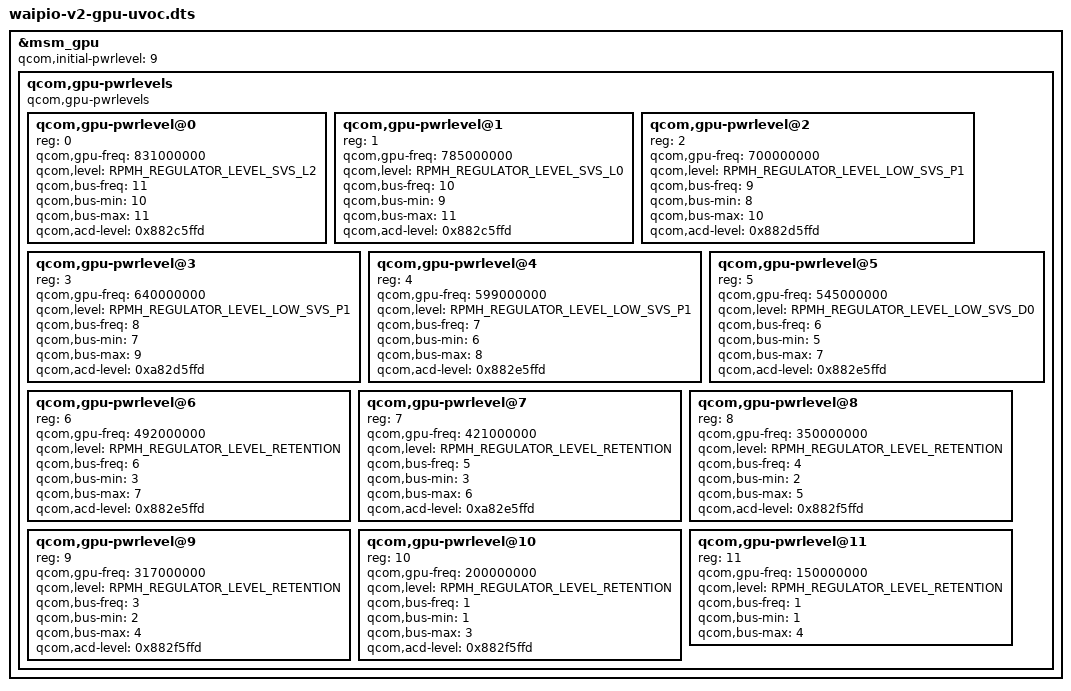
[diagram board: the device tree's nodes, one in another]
/*
 * DoraCore: waipio-v2.dtb with an Adreno 730 undervolt + overclock
 * power level table, from the KonaBess profile "new 831-150 uv_oc".
 * Generated by tools/gen-gpu-profiles.py; only the GPU (GX) rail
 * levels change, CX votes stay as stock. Running the GPU outside the
 * stock table may crash, freeze or damage the device.
 */

#include "waipio-v2.dts"

&msm_gpu {
	/delete-node/ qcom,gpu-pwrlevels;
};

&msm_gpu {
	qcom,initial-pwrlevel = <9>;

	qcom,gpu-pwrlevels {
		#address-cells = <1>;
		#size-cells = <0>;

		compatible = "qcom,gpu-pwrlevels";

		/* 831 MHz (not in stock, profile level 193) */
		qcom,gpu-pwrlevel@0 {
			reg = <0>;
			qcom,gpu-freq = <831000000>;
			qcom,level = <RPMH_REGULATOR_LEVEL_SVS_L2>;

			qcom,bus-freq = <11>;
			qcom,bus-min = <10>;
			qcom,bus-max = <11>;

			qcom,acd-level = <0x882c5ffd>;
		};

		/* 785 MHz (not in stock, profile level 129) */
		qcom,gpu-pwrlevel@1 {
			reg = <1>;
			qcom,gpu-freq = <785000000>;
			qcom,level = <RPMH_REGULATOR_LEVEL_SVS_L0>;

			qcom,bus-freq = <10>;
			qcom,bus-min = <9>;
			qcom,bus-max = <11>;

			qcom,acd-level = <0x882c5ffd>;
		};

		/* 700 MHz (not in stock, profile level 65) */
		qcom,gpu-pwrlevel@2 {
			reg = <2>;
			qcom,gpu-freq = <700000000>;
			qcom,level = <RPMH_REGULATOR_LEVEL_LOW_SVS_P1>;

			qcom,bus-freq = <9>;
			qcom,bus-min = <8>;
			qcom,bus-max = <10>;

			qcom,acd-level = <0x882d5ffd>;
		};

		/* 640 MHz (stock SVS_L2, profile level 65) */
		qcom,gpu-pwrlevel@3 {
			reg = <3>;
			qcom,gpu-freq = <640000000>;
			qcom,level = <RPMH_REGULATOR_LEVEL_LOW_SVS_P1>;

			qcom,bus-freq = <8>;
			qcom,bus-min = <7>;
			qcom,bus-max = <9>;

			qcom,acd-level = <0xa82d5ffd>;
		};

		/* 599 MHz (stock SVS_L1, profile level 65) */
		qcom,gpu-pwrlevel@4 {
			reg = <4>;
			qcom,gpu-freq = <599000000>;
			qcom,level = <RPMH_REGULATOR_LEVEL_LOW_SVS_P1>;

			qcom,bus-freq = <7>;
			qcom,bus-min = <6>;
			qcom,bus-max = <8>;

			qcom,acd-level = <0x882e5ffd>;
		};

		/* 545 MHz (stock SVS_L0, profile level 57) */
		qcom,gpu-pwrlevel@5 {
			reg = <5>;
			qcom,gpu-freq = <545000000>;
			qcom,level = <RPMH_REGULATOR_LEVEL_LOW_SVS_D0>;

			qcom,bus-freq = <6>;
			qcom,bus-min = <5>;
			qcom,bus-max = <7>;

			qcom,acd-level = <0x882e5ffd>;
		};

		/* 492 MHz (stock SVS, profile level 5) */
		qcom,gpu-pwrlevel@6 {
			reg = <6>;
			qcom,gpu-freq = <492000000>;
			qcom,level = <RPMH_REGULATOR_LEVEL_RETENTION>;

			qcom,bus-freq = <6>;
			qcom,bus-min = <3>;
			qcom,bus-max = <7>;

			qcom,acd-level = <0x882e5ffd>;
		};

		/* 421 MHz (stock LOW_SVS_L1, profile level 1) */
		qcom,gpu-pwrlevel@7 {
			reg = <7>;
			qcom,gpu-freq = <421000000>;
			qcom,level = <RPMH_REGULATOR_LEVEL_RETENTION>;

			qcom,bus-freq = <5>;
			qcom,bus-min = <3>;
			qcom,bus-max = <6>;

			qcom,acd-level = <0xa82e5ffd>;
		};

		/* 350 MHz (stock LOW_SVS, profile level 1) */
		qcom,gpu-pwrlevel@8 {
			reg = <8>;
			qcom,gpu-freq = <350000000>;
			qcom,level = <RPMH_REGULATOR_LEVEL_RETENTION>;

			qcom,bus-freq = <4>;
			qcom,bus-min = <2>;
			qcom,bus-max = <5>;

			qcom,acd-level = <0x882f5ffd>;
		};

		/* 317 MHz (stock LOW_SVS, profile level 1) */
		qcom,gpu-pwrlevel@9 {
			reg = <9>;
			qcom,gpu-freq = <317000000>;
			qcom,level = <RPMH_REGULATOR_LEVEL_RETENTION>;

			qcom,bus-freq = <3>;
			qcom,bus-min = <2>;
			qcom,bus-max = <4>;

			qcom,acd-level = <0x882f5ffd>;
		};

		/* 200 MHz (not in stock, profile level 1) */
		qcom,gpu-pwrlevel@10 {
			reg = <10>;
			qcom,gpu-freq = <200000000>;
			qcom,level = <RPMH_REGULATOR_LEVEL_RETENTION>;

			qcom,bus-freq = <1>;
			qcom,bus-min = <1>;
			qcom,bus-max = <3>;

			qcom,acd-level = <0x882f5ffd>;
		};

		/* 150 MHz (not in stock, profile level 1) */
		qcom,gpu-pwrlevel@11 {
			reg = <11>;
			qcom,gpu-freq = <150000000>;
			qcom,level = <RPMH_REGULATOR_LEVEL_RETENTION>;

			qcom,bus-freq = <1>;
			qcom,bus-min = <1>;
			qcom,bus-max = <4>;
		};
	};
};
